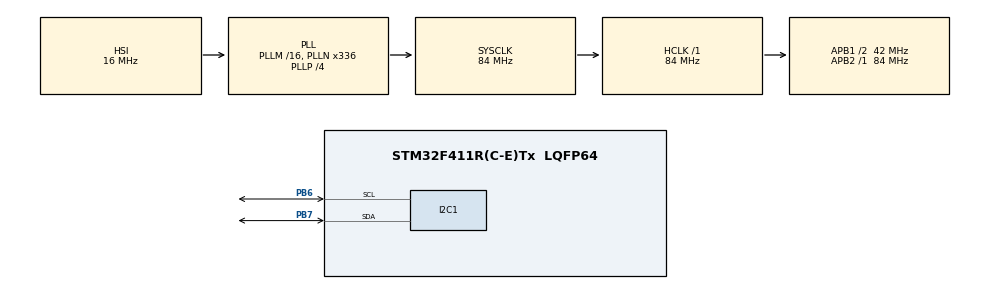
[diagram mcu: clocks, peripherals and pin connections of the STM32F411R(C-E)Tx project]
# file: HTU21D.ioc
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Mcu.Family=STM32F4
Mcu.Name=STM32F411R(C-E)Tx
Mcu.Package=LQFP64
NVIC.PriorityGroup=NVIC_PRIORITYGROUP_0
PA13.GPIO_Label=TMS
PA13.Mode=Serial_Wire
PA13.Signal=SYS_JTMS-SWDIO
PA14.GPIO_Label=TCK
PA14.Mode=Serial_Wire
PA14.Signal=SYS_JTCK-SWCLK
PB3.GPIO_Label=SWO
PB3.Signal=SYS_JTDO-SWO
PB6.Mode=I2C
PB6.Signal=I2C1_SCL
PB7.Mode=I2C
PB7.Signal=I2C1_SDA
PC14-OSC32_IN.Signal=RCC_OSC32_IN
PC15-OSC32_OUT.Signal=RCC_OSC32_OUT
PH0\ -\ OSC_IN.Signal=RCC_OSC_IN
PH1\ -\ OSC_OUT.Signal=RCC_OSC_OUT
ProjectManager.HeapSize=0x200
ProjectManager.StackSize=0x400
ProjectManager.TargetToolchain=STM32CubeIDE
RCC.48MHZClocksFreq_Value=84000000
RCC.AHBFreq_Value=84000000
RCC.APB1CLKDivider=RCC_HCLK_DIV2
RCC.APB1Freq_Value=42000000
RCC.APB1TimFreq_Value=84000000
RCC.APB2Freq_Value=84000000
RCC.APB2TimFreq_Value=84000000
RCC.CortexFreq_Value=84000000
RCC.FLatency-AdvancedSettings=FLASH_LATENCY_2
RCC.HCLKFreq_Value=84000000
RCC.HSE_VALUE=8000000
RCC.HSI_VALUE=16000000
RCC.LSE_VALUE=32768
RCC.PLLN=336
RCC.PLLP=RCC_PLLP_DIV4
RCC.SYSCLKFreq_VALUE=84000000
RCC.SYSCLKSource=RCC_SYSCLKSOURCE_PLLCLK
RCC.VCOOutputFreq_Value=336000000
board=NUCLEO-F411RE

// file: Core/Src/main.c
/* USER CODE BEGIN Header */
/**
  ******************************************************************************
  * @file           : main.c
  * @brief          : Main program body
  ******************************************************************************
  * @attention
  *
  * Copyright (c) 2023 STMicroelectronics.
  * All rights reserved.
  *
  * This software is licensed under terms that can be found in the LICENSE file
  * in the root directory of this software component.
  * If no LICENSE file comes with this software, it is provided AS-IS.
  *
  ******************************************************************************
  */
/* USER CODE END Header */
#include "main.h"

/* USER CODE BEGIN PD */
#define		TEMP_MEASUREMENT	0xE3
#define		HUMI_MEASUREMENT	0xE5
#define		WRITE_REGISTER		0xE6
#define		READ_REGISTER		0xE7
#define		DEVICE_ADDRESS      0x40
/* USER CODE END PD */

I2C_HandleTypeDef hi2c1;

void SystemClock_Config(void);
static void MX_GPIO_Init(void);
static void MX_I2C1_Init(void);
/* USER CODE BEGIN PFP */
void HTU21D_SensorInit(void);
void HTU21D_Measurement(uint8_t cmd);
/* USER CODE END PFP */

/* USER CODE BEGIN 0 */
float temp;
float humidity;
/* USER CODE END 0 */

int main(void)
{
  /* USER CODE BEGIN 1 */
	uint8_t cmd[] = {TEMP_MEASUREMENT, HUMI_MEASUREMENT};
	uint8_t i = 0;
  /* USER CODE END 1 */

  /* MCU Configuration--------------------------------------------------------*/

  /* Reset of all peripherals, Initializes the Flash interface and the Systick. */
  HAL_Init();

  /* USER CODE BEGIN Init */
  HTU21D_SensorInit();
  /* USER CODE END Init */

  /* Configure the system clock */
  SystemClock_Config();

  /* Initialize all configured peripherals */
  MX_GPIO_Init();
  MX_I2C1_Init();

  /* Infinite loop */
  while (1)
  {
	  HTU21D_Measurement(cmd[i % 2]);
	  ++i;
  }
}

void SystemClock_Config(void)
{
  RCC_OscInitTypeDef RCC_OscInitStruct = {0};
  RCC_ClkInitTypeDef RCC_ClkInitStruct = {0};

  /** Configure the main internal regulator output voltage
  */
  __HAL_RCC_PWR_CLK_ENABLE();
  __HAL_PWR_VOLTAGESCALING_CONFIG(PWR_REGULATOR_VOLTAGE_SCALE1);

  /** Initializes the RCC Oscillators according to the specified parameters
  * in the RCC_OscInitTypeDef structure.
  */
  RCC_OscInitStruct.OscillatorType = RCC_OSCILLATORTYPE_HSI;
  RCC_OscInitStruct.HSIState = RCC_HSI_ON;
  RCC_OscInitStruct.HSICalibrationValue = RCC_HSICALIBRATION_DEFAULT;
  RCC_OscInitStruct.PLL.PLLState = RCC_PLL_ON;
  RCC_OscInitStruct.PLL.PLLSource = RCC_PLLSOURCE_HSI;
  RCC_OscInitStruct.PLL.PLLM = 16;
  RCC_OscInitStruct.PLL.PLLN = 336;
  RCC_OscInitStruct.PLL.PLLP = RCC_PLLP_DIV4;
  RCC_OscInitStruct.PLL.PLLQ = 4;
  if (HAL_RCC_OscConfig(&RCC_OscInitStruct) != HAL_OK)
  {
    Error_Handler();
  }

  /** Initializes the CPU, AHB and APB buses clocks
  */
  RCC_ClkInitStruct.ClockType = RCC_CLOCKTYPE_HCLK|RCC_CLOCKTYPE_SYSCLK
                              |RCC_CLOCKTYPE_PCLK1|RCC_CLOCKTYPE_PCLK2;
  RCC_ClkInitStruct.SYSCLKSource = RCC_SYSCLKSOURCE_PLLCLK;
  RCC_ClkInitStruct.AHBCLKDivider = RCC_SYSCLK_DIV1;
  RCC_ClkInitStruct.APB1CLKDivider = RCC_HCLK_DIV2;
  RCC_ClkInitStruct.APB2CLKDivider = RCC_HCLK_DIV1;

  if (HAL_RCC_ClockConfig(&RCC_ClkInitStruct, FLASH_LATENCY_2) != HAL_OK)
  {
    Error_Handler();
  }
}

static void MX_I2C1_Init(void)
{

  hi2c1.Instance = I2C1;
  hi2c1.Init.ClockSpeed = 100000;
  hi2c1.Init.DutyCycle = I2C_DUTYCYCLE_2;
  hi2c1.Init.OwnAddress1 = 0;
  hi2c1.Init.AddressingMode = I2C_ADDRESSINGMODE_7BIT;
  hi2c1.Init.DualAddressMode = I2C_DUALADDRESS_DISABLE;
  hi2c1.Init.OwnAddress2 = 0;
  hi2c1.Init.GeneralCallMode = I2C_GENERALCALL_DISABLE;
  hi2c1.Init.NoStretchMode = I2C_NOSTRETCH_DISABLE;
  if (HAL_I2C_Init(&hi2c1) != HAL_OK)
  {
    Error_Handler();
  }

}

static void MX_GPIO_Init(void)
{

  /* GPIO Ports Clock Enable */
  __HAL_RCC_GPIOC_CLK_ENABLE();
  __HAL_RCC_GPIOH_CLK_ENABLE();
  __HAL_RCC_GPIOA_CLK_ENABLE();
  __HAL_RCC_GPIOB_CLK_ENABLE();

}

/* USER CODE BEGIN 4 */
void HTU21D_SensorInit(void)
{
	uint8_t pData[] = {0xFE}; // SOFT_RESET
	HAL_I2C_Mem_Write(&hi2c1, (DEVICE_ADDRESS << 1), WRITE_REGISTER, 1, pData, 1, 100);
	HAL_Delay(15);
}

void HTU21D_Measurement(uint8_t cmd)
{
	uint8_t pData[] = {cmd};
	uint8_t measurement[2];
	uint16_t raw_measurement;
	if(HAL_I2C_Master_Transmit(&hi2c1, DEVICE_ADDRESS, pData, 1, 100))
	{
		Error_Handler();
	}
	if(HAL_I2C_Master_Receive(&hi2c1, DEVICE_ADDRESS, measurement, 2, 100))
	{
		Error_Handler();
	}
	raw_measurement = (measurement[1] << 8) | measurement[0];
	if (cmd == TEMP_MEASUREMENT)
		temp = -46.85 + 175.72 * raw_measurement / 65536;
	else if (cmd == HUMI_MEASUREMENT)
		humidity = -6 + 125 * raw_measurement / 65536;
}
/* USER CODE END 4 */
void Error_Handler(void)
{
  __disable_irq();
  while (1)
  {
  }
}
